# S32K148_M4 register map
Vendor: NXP Semiconductors; File version: 1.1a
CPU: CM4 r0p1, little endian, MPU, FPU, VTOR, 4 interrupt priority bits
Registers are 32-bit, read-write, reset 0x0 unless marked. A register's access mark holds for its fields unless they carry their own. Offsets are from the block's base; [hi:lo] are bit positions; {n}, {i} and the like mark numbered series; 'fields as' and 'values as' point back to an identical list.

## ERM
Base 0x40018000
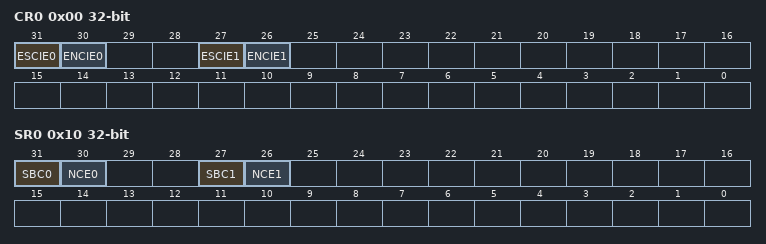
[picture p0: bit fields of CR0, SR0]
0x00 CR0 — ERM Configuration Register 0
  [31] ESCIE0
    0=Interrupt notification of Memory 0 single-bit correction events is disabled; 1=Interrupt notification of Memory 0 single-bit correction events is enabled
  [30] ENCIE0
    0=Interrupt notification of Memory 0 non-correctable error events is disabled; 1=Interrupt notification of Memory 0 non-correctable error events is enabled
  [27] ESCIE1
    0=Interrupt notification of Memory 1 single-bit correction events is disabled; 1=Interrupt notification of Memory 1 single-bit correction events is enabled
  [26] ENCIE1
    0=Interrupt notification of Memory 1 non-correctable error events is disabled; 1=Interrupt notification of Memory 1 non-correctable error events is enabled
0x10 SR0 write-1-clears — ERM Status Register 0
  [31] SBC0 write-1-clears
    0=No single-bit correction event on Memory 0 detected; 1=Single-bit correction event on Memory 0 detected
  [30] NCE0 write-1-clears
    0=No non-correctable error event on Memory 0 detected; 1=Non-correctable error event on Memory 0 detected
  [27] SBC1 write-1-clears
    0=No single-bit correction event on Memory 1 detected; 1=Single-bit correction event on Memory 1 detected
  [26] NCE1 write-1-clears
    0=No non-correctable error event on Memory 1 detected; 1=Non-correctable error event on Memory 1 detected
0x100 EAR0 ro — ERM Memory n Error Address Register
  [31:0] EAR
0x110 EAR1 ro — ERM Memory n Error Address Register
  [31:0] EAR

## EIM
Base 0x40019000
0x00 EIMCR — Error Injection Module Configuration Register
  [0] GEIEN — Global Error Injection Enable
    0=Disabled; 1=Enabled
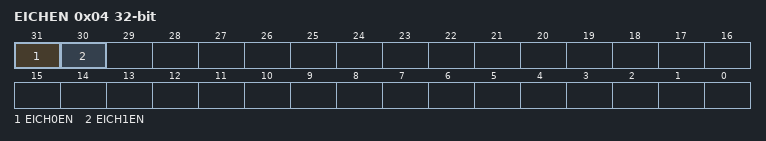
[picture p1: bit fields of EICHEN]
0x04 EICHEN — Error Injection Channel Enable register
  [31] EICH0EN — Error Injection Channel 0 Enable
    0=Error injection is disabled on Error Injection Channel 0; 1=Error injection is enabled on Error Injection Channel 0
  [30] EICH1EN — Error Injection Channel 1 Enable
    0=Error injection is disabled on Error Injection Channel 1; 1=Error injection is enabled on Error Injection Channel 1
0x100 EICHD0_WORD0 — Error Injection Channel Descriptor n, Word0
  [31:25] CHKBIT_MASK — Checkbit Mask
0x104 EICHD0_WORD1 — Error Injection Channel Descriptor n, Word1
  [31:0] B0_3DATA_MASK — Data Mask Bytes 0-3
0x200 EICHD1_WORD0 — Error Injection Channel Descriptor n, Word0
  [31:25] CHKBIT_MASK — Checkbit Mask
0x204 EICHD1_WORD1 — Error Injection Channel Descriptor n, Word1
  [31:0] B0_3DATA_MASK — Data Mask Bytes 0-3

## DMAMUX
Base 0x40021000
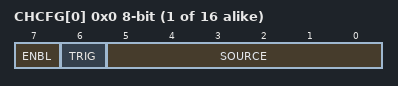
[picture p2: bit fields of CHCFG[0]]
{0x0+i} CHCFG[{i}] (i=0..15) 8-bit — Channel Configuration register
  [7] ENBL — DMA Channel Enable
    0=DMA channel is disabled. This mode is primarily used during configuration of the DMAMux. The DMA has separate channel enables/disables, which should be used to disable or reconfigure a DMA channel.; 1=DMA channel is enabled
  [6] TRIG — DMA Channel Trigger Enable
    0=Triggering is disabled. If triggering is disabled and ENBL is set, the DMA Channel will simply route the specified source to the DMA channel. (Normal mode); 1=Triggering is enabled. If triggering is enabled and ENBL is set, the DMAMUX is in Periodic Trigger mode.
  [5:0] SOURCE — DMA Channel Source (Slot)

## CRC
Base 0x40032000
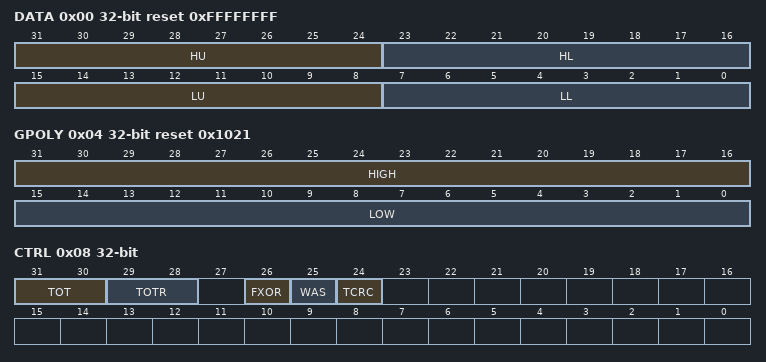
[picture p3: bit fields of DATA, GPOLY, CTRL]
0x00 DATA reset 0xFFFFFFFF — CRC Data register
  [31:24] HU — CRC High Upper Byte
  [23:16] HL — CRC High Lower Byte
  [15:8] LU — CRC Low Upper Byte
  [7:0] LL — CRC Low Lower Byte
0x04 GPOLY reset 0x1021 — CRC Polynomial register
  [31:16] HIGH — High Polynominal Half-word
  [15:0] LOW — Low Polynominal Half-word
0x08 CTRL — CRC Control register
  [31:30] TOT — Type Of Transpose For Writes
    0=No transposition; 1=Bits in bytes are transposed; bytes are not transposed; 2=Both bits in bytes and bytes are transposed; 3=Only bytes are transposed; no bits in a byte are transposed
  [29:28] TOTR — Type Of Transpose For Read
    values as TOT
  [26] FXOR — Complement Read Of CRC Data Register
    0=No XOR on reading; 1=Invert or complement the read value of the CRC Data register
  [25] WAS — Write CRC Data Register As Seed
    0=Writes to the CRC data register are data values; 1=Writes to the CRC data register are seed values
  [24] TCRC
    0=16-bit CRC protocol; 1=32-bit CRC protocol
